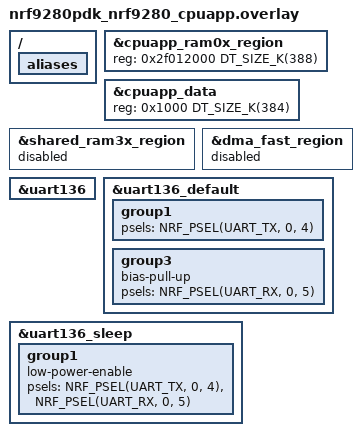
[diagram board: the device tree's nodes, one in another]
/ {
	/* Delete these aliases because the button nodes are deleted. */
	aliases {
		/delete-property/ sw0;
		/delete-property/ sw1;
		/delete-property/ sw3;
	};
};

/* Remove buttons because they conflict with modem pin allocations. */
/delete-node/ &button0;
/delete-node/ &button1;
/delete-node/ &button3;

// Should be fixed in zephyr upstream
/* Reduce application ram0x size from 512kB to 256kB because last part of that
 * memory conflicted with modem allocation.
 */
&cpuapp_ram0x_region {
	reg = <0x2f012000 DT_SIZE_K(388)>;
	ranges = <0x0 0x2f012000 0x61000>;
};
&cpuapp_data {
	reg = <0x1000 DT_SIZE_K(384)>;
};

// Should be fixed in zephyr upstream
/* Access given by default. Blocks boot if access is asked for through UICR. */
&shared_ram3x_region {
	status = "disabled";
};

&dma_fast_region {
        status = "disabled";
};

/* Disable HW flow control for the application UART. CTS is connected to pin P0.0, but
 * pins 0..3 cannot be used for UARTE signals.
 */
&uart136 {
	/*current-speed = <1000000>;*/
	/delete-property/ hw-flow-control;
};

&uart136_default {
	group1 {
		psels = <NRF_PSEL(UART_TX, 0, 4)>;
	};
	group3 {
		bias-pull-up;
		psels = <NRF_PSEL(UART_RX, 0, 5)>;
	};
};
&uart136_sleep {
	group1 {
		low-power-enable;
		psels = <NRF_PSEL(UART_TX, 0, 4)>,
			<NRF_PSEL(UART_RX, 0, 5)>;
	};
};
